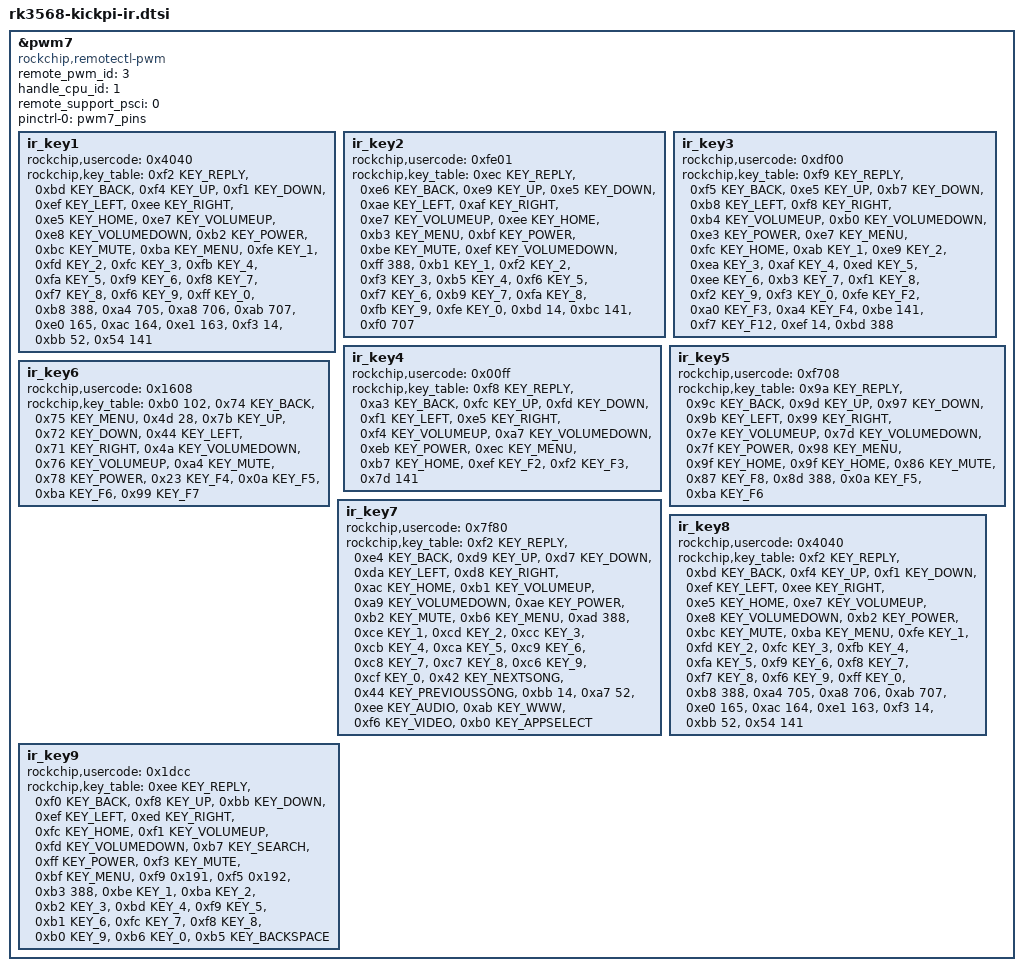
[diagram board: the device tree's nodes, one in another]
&pwm7 {
    status = "okay";
    compatible = "rockchip,remotectl-pwm";
    remote_pwm_id = <3>;
    handle_cpu_id = <1>;
    remote_support_psci = <0>;
    pinctrl-names = "default";
    pinctrl-0 = <&pwm7_pins>;
		ir_key1{
		rockchip,usercode = <0x4040>;
		rockchip,key_table =
//			<0xf2	KEY_ENTER>,
			<0xf2	KEY_REPLY>,
//			<0xf2	KEY_OK>,
			<0xbd	KEY_BACK>,
			<0xf4	KEY_UP>,
			<0xf1	KEY_DOWN>,
			<0xef	KEY_LEFT>,
			<0xee	KEY_RIGHT>,
			<0xe5	KEY_HOME>,
			<0xe7	KEY_VOLUMEUP>,
			<0xe8	KEY_VOLUMEDOWN>,
					 
			<0xb2	KEY_POWER>,
			<0xbc	KEY_MUTE>,
			<0xba	KEY_MENU>,
			<0xfe	KEY_1>,
			<0xfd	KEY_2>,
			<0xfc	KEY_3>,
			<0xfb	KEY_4>,
			<0xfa	KEY_5>,
			<0xf9	KEY_6>,
			<0xf8	KEY_7>,
			<0xf7	KEY_8>,
			<0xf6	KEY_9>,
			<0xff	KEY_0>,
			<0xb8	388>,              // mouse
			<0xa4	705>,             //705   PROG_GREEN
			<0xa8	706>,             //706   PROG_YELLOW
			<0xab	707>,             //707   PROG_BLUE
			<0xe0	165>,             //165   MEDIA_PREVIOUS
			<0xac	164>,             //164   MEDIA_PLAY_PAUSE
			<0xe1	163>,             //163   MEDIA_NEXT
			<0xf3	14>,              //14    DEL
			<0xbb	52>,              //52    PERIOD
			<0x54	141>;             //141   SETTINGS
	};

	ir_key2{
		rockchip,usercode = <0xfe01>;
		rockchip,key_table =
			<0xec	KEY_REPLY>,
			<0xe6	KEY_BACK>,
			<0xe9	KEY_UP>,
			<0xe5	KEY_DOWN>,
			<0xae	KEY_LEFT>,
			<0xaf	KEY_RIGHT>,
			<0xe7	KEY_VOLUMEUP>,
			<0xee	KEY_HOME>,
			<0xb3	KEY_MENU>,
			<0xbf	KEY_POWER>,
			<0xbe	KEY_MUTE>,
			<0xef	KEY_VOLUMEDOWN>,
			<0xff	388>,
			<0xb1	KEY_1>,
			<0xf2	KEY_2>,
			<0xf3	KEY_3>,
			<0xb5	KEY_4>,
			<0xf6	KEY_5>,
			<0xf7	KEY_6>,
			<0xb9	KEY_7>,
			<0xfa	KEY_8>,
			<0xfb	KEY_9>,
			<0xfe	KEY_0>,
			<0xbd	14>,
			<0xbc	141>,
			<0xf0	707>;
	};

	ir_key3{
		rockchip,usercode = <0xdf00>;
		rockchip,key_table =
			<0xf9	KEY_REPLY>,
			<0xf5	KEY_BACK>,
			<0xe5	KEY_UP>,
			<0xb7	KEY_DOWN>,
			<0xb8	KEY_LEFT>,
			<0xf8	KEY_RIGHT>,
			<0xb4	KEY_VOLUMEUP>,
			<0xb0	KEY_VOLUMEDOWN>,
			<0xe3	KEY_POWER>,
			<0xe7	KEY_MENU>,
			<0xfc	KEY_HOME>,
			<0xab	KEY_1>,
			<0xe9	KEY_2>,
			<0xea	KEY_3>,
			<0xaf	KEY_4>,
			<0xed	KEY_5>,
			<0xee	KEY_6>,
			<0xb3	KEY_7>,
			<0xf1	KEY_8>,
			<0xf2	KEY_9>,
			<0xf3	KEY_0>,
			<0xfe	KEY_F2>,  //tv
			<0xa0	KEY_F3>,    //vod
			<0xa4	KEY_F4>,    //app
			<0xbe	141>,           //141   SETTINGS
			<0xf7	KEY_F12>,   //flip  KEY_MUTE
			<0xef	14>,          //14    DEL
			<0xbd	388>;            //mouse
	};

	ir_key4{
		rockchip,usercode = <0x00ff>;
		rockchip,key_table =
			<0xf8	KEY_REPLY>,
			<0xa3	KEY_BACK>,
			<0xfc	KEY_UP>,
			<0xfd	KEY_DOWN>,
			<0xf1	KEY_LEFT>,
			<0xe5	KEY_RIGHT>,
			<0xf4	KEY_VOLUMEUP>,
			<0xa7	KEY_VOLUMEDOWN>,
			<0xeb	KEY_POWER>,
			<0xec	KEY_MENU>,
			<0xb7	KEY_HOME>,
			<0xef	KEY_F2>,
			<0xf2	KEY_F3>,
			<0x7d	141>;             //141   SETTINGS
	};
	ir_key5{
		rockchip,usercode = <0xf708>;
		rockchip,key_table =
			<0x9a	KEY_REPLY>,
			<0x9c	KEY_BACK>,
			<0x9d	KEY_UP>,
			<0x97	KEY_DOWN>,
			<0x9b	KEY_LEFT>,
			<0x99	KEY_RIGHT>,
			<0x7e	KEY_VOLUMEUP>,
			<0x7d	KEY_VOLUMEDOWN>,
			<0x7f	KEY_POWER>,
			<0x98	KEY_MENU>,
			<0x9f	KEY_HOME>,
      <0x9f   KEY_HOME>,
      <0x86   KEY_MUTE>,
      <0x87   KEY_F8>,      //adjust projector
      <0x8d   388>,            //mouse
		  <0x0a   KEY_F5>,      //TV
      <0xba   KEY_F6>;            //VOD
	};
  ir_key6{
    rockchip,usercode = <0x1608>;
    rockchip,key_table =
      <0xb0   102>,    //home
      <0x74   KEY_BACK>,
      <0x75   KEY_MENU>,
      <0x4d   28>,
      <0x7b   KEY_UP>,
      <0x72   KEY_DOWN>,
      <0x44   KEY_LEFT>,
      <0x71   KEY_RIGHT>,
      <0x4a   KEY_VOLUMEDOWN>,
      <0x76   KEY_VOLUMEUP>,
      <0xa4   KEY_MUTE>,
      <0x78   KEY_POWER>,
      <0x23   KEY_F4>,
      <0x0a   KEY_F5>,
      <0xba   KEY_F6>,
      <0x99   KEY_F7>;
  };
	ir_key7{
		rockchip,usercode = <0x7f80>;
		rockchip,key_table =
			<0xf2	KEY_REPLY>,
			<0xe4	KEY_BACK>,
			<0xd9	KEY_UP>,
			<0xd7	KEY_DOWN>,
			<0xda	KEY_LEFT>,
			<0xd8	KEY_RIGHT>,
			<0xac	KEY_HOME>,
			<0xb1	KEY_VOLUMEUP>,
			<0xa9	KEY_VOLUMEDOWN>,
			<0xae	KEY_POWER>,
			<0xb2	KEY_MUTE>,
			<0xb6	KEY_MENU>,
			<0xad	388>,
			<0xce	KEY_1>,
			<0xcd	KEY_2>,
			<0xcc	KEY_3>,
			<0xcb	KEY_4>,
			<0xca	KEY_5>,
			<0xc9	KEY_6>,
			<0xc8	KEY_7>,
			<0xc7	KEY_8>,
			<0xc6	KEY_9>,
			<0xcf	KEY_0>,
			// <0x42	165>,
			<0x42	KEY_NEXTSONG>,
			// <0x44	163>,
			<0x44	KEY_PREVIOUSSONG>,
			<0xbb	14>,
			<0xa7	52>,
			// <0xee	705>,
			// <0xab	706>,
			// <0xf6	704>,
			// <0xb0	707>;
			<0xee	KEY_AUDIO>,
			<0xab	KEY_WWW>,
			<0xf6	KEY_VIDEO>,
			<0xb0	KEY_APPSELECT>;
	};

	ir_key8{
		rockchip,usercode = <0x4040>;
		rockchip,key_table =
			<0xf2	KEY_REPLY>,
			<0xbd	KEY_BACK>,
			<0xf4	KEY_UP>,
			<0xf1	KEY_DOWN>,
			<0xef	KEY_LEFT>,
			<0xee	KEY_RIGHT>,
			<0xe5	KEY_HOME>,
			<0xe7	KEY_VOLUMEUP>,
			<0xe8	KEY_VOLUMEDOWN>,
			<0xb2	KEY_POWER>,
			<0xbc	KEY_MUTE>,
			<0xba	KEY_MENU>,
			<0xfe	KEY_1>,
			<0xfd	KEY_2>,
			<0xfc	KEY_3>,
			<0xfb	KEY_4>,
			<0xfa	KEY_5>,
			<0xf9	KEY_6>,
			<0xf8	KEY_7>,
			<0xf7	KEY_8>,
			<0xf6	KEY_9>,
			<0xff	KEY_0>,
			<0xb8	388>,
			<0xa4	705>,             //705   PROG_GREEN
			<0xa8	706>,             //706   PROG_YELLOW
			<0xab	707>,             //707   PROG_BLUE
			<0xe0	165>,             //165   MEDIA_PREVIOUS
			<0xac	164>,             //164   MEDIA_PLAY_PAUSE
			<0xe1	163>,             //163   MEDIA_NEXT
			<0xf3	14>,              //14    DEL
			<0xbb	52>,              //52    PERIOD
			<0x54	141>;             //141   SETTINGS
	};
	
	ir_key9 {
		rockchip,usercode = <0x1dcc>;
		rockchip,key_table =
			<0xee	KEY_REPLY>,
			<0xf0	KEY_BACK>,
			<0xf8	KEY_UP>,
			<0xbb	KEY_DOWN>,
			<0xef	KEY_LEFT>,
			<0xed	KEY_RIGHT>,
			<0xfc	KEY_HOME>,
			<0xf1	KEY_VOLUMEUP>,
			<0xfd	KEY_VOLUMEDOWN>,
			<0xb7	KEY_SEARCH>,
			<0xff	KEY_POWER>,
			<0xf3	KEY_MUTE>,
			<0xbf	KEY_MENU>,
			<0xf9	0x191>,
			<0xf5	0x192>,
			<0xb3	388>,
			<0xbe	KEY_1>,
			<0xba	KEY_2>,
			<0xb2	KEY_3>,
			<0xbd	KEY_4>,
			<0xf9	KEY_5>,
			<0xb1	KEY_6>,
			<0xfc	KEY_7>,
			<0xf8	KEY_8>,
			<0xb0	KEY_9>,
			<0xb6	KEY_0>,
			<0xb5	KEY_BACKSPACE>;
	};
};

